# ESP32-P4 register map
Vendor: ESPRESSIF SYSTEMS (SHANGHAI) CO., LTD.; Series: ESP32 P-Series; File version: 3
CPU: RV32IMAFC r0p0, little endian, no MPU, FPU, 0 interrupt priority bits
Address unit: 32 bits
Registers are 32-bit, read-write, reset 0x0 unless marked. A register's access mark holds for its fields unless they carry their own. Offsets are from the block's base; [hi:lo] are bit positions; {n}, {i} and the like mark numbered series.

## LP_WDT — Low-power Watchdog Timer
Base 0x50116000
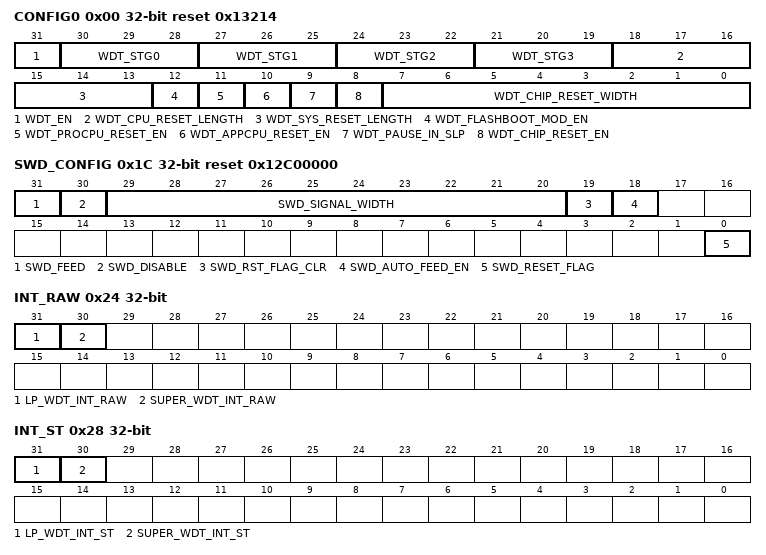
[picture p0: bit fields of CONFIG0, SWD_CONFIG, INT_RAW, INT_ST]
0x00 CONFIG0 reset 0x13214 — need_des
  [31] WDT_EN — need_des
  [30-3n:28-3n] WDT_STG{n} (n=0..3) — need_des
  [18:16] WDT_CPU_RESET_LENGTH — need_des
  [15:13] WDT_SYS_RESET_LENGTH — need_des
  [12] WDT_FLASHBOOT_MOD_EN — need_des
  [11] WDT_PROCPU_RESET_EN — need_des
  [10] WDT_APPCPU_RESET_EN — need_des
  [9] WDT_PAUSE_IN_SLP — need_des
  [8] WDT_CHIP_RESET_EN — need_des
  [7:0] WDT_CHIP_RESET_WIDTH — need_des
0x04 CONFIG1 reset 0x30D40 — need_des
  [31:0] WDT_STG0_HOLD
0x08 CONFIG2 reset 0x13880 — need_des
  [31:0] WDT_STG1_HOLD
0x0C CONFIG3 reset 0xFFF — need_des
  [31:0] WDT_STG2_HOLD
0x10 CONFIG4 reset 0xFFF — need_des
  [31:0] WDT_STG3_HOLD
0x14 FEED wo — need_des
  [31] FEED
0x18 WPROTECT — need_des
  [31:0] WDT_WKEY
0x1C SWD_CONFIG access per field reset 0x12C00000 — need_des
  [31] SWD_FEED wo — need_des
  [30] SWD_DISABLE rw — need_des
  [29:20] SWD_SIGNAL_WIDTH rw — need_des
  [19] SWD_RST_FLAG_CLR wo — need_des
  [18] SWD_AUTO_FEED_EN rw — need_des
  [0] SWD_RESET_FLAG ro — need_des
0x20 SWD_WPROTECT — need_des
  [31:0] SWD_WKEY
0x24 INT_RAW — need_des
  [31] LP_WDT_INT_RAW — need_des
  [30] SUPER_WDT_INT_RAW — need_des
0x28 INT_ST ro — need_des
  [31] LP_WDT_INT_ST — need_des
  [30] SUPER_WDT_INT_ST — need_des
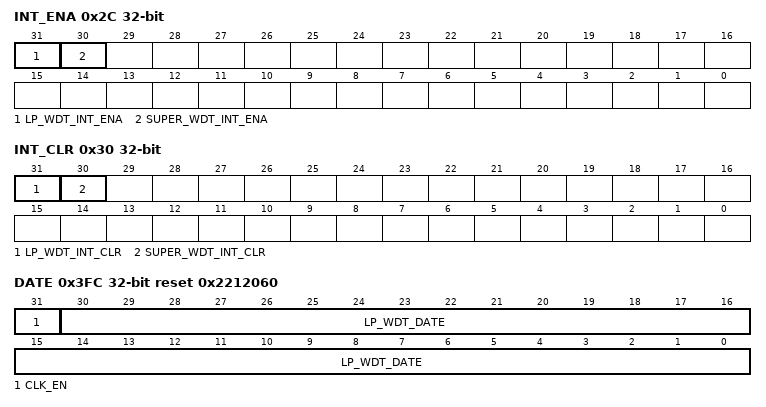
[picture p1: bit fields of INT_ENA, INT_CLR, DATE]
0x2C INT_ENA — need_des
  [31] LP_WDT_INT_ENA — need_des
  [30] SUPER_WDT_INT_ENA — need_des
0x30 INT_CLR wo — need_des
  [31] LP_WDT_INT_CLR — need_des
  [30] SUPER_WDT_INT_CLR — need_des
0x3FC DATE reset 0x2212060 — need_des
  [31] CLK_EN — need_des
  [30:0] LP_WDT_DATE — need_des

## SHA — SHA (Secure Hash Algorithm) Accelerator
Base 0x50091000
0x00 MODE — Configures SHA algorithm
  [2:0] MODE — Configures the SHA algorithm. \\ 0: SHA-1\\ 1: SHA-224\\ 2: SHA-256\\ 3: SHA2-384\\ 4: SHA2-512\\ 5: SHA2-512/224\\ 6: SHA2-512/256\\ 7: SHA2-512/t\\
0x04 T_STRING — SHA 512/t configuration register 0.
  [31:0] T_STRING — Sha t_string (used if and only if mode == SHA_512/t).
0x08 T_LENGTH — SHA 512/t configuration register 1.
  [6:0] T_LENGTH — Sha t_length (used if and only if mode == SHA_512/t).
0x0C DMA_BLOCK_NUM — Block number register (only effective for DMA-SHA)
  [15:0] DMA_BLOCK_NUM — Configures the DMA-SHA block number.
0x10 START wo — Starts the SHA accelerator for Typical SHA operation
  [0] START — Write 1 to start Typical SHA calculation.
0x14 CONTINUE wo — Continues SHA operation (only effective in Typical SHA mode)
  [0] CONTINUE — Write 1 to continue Typical SHA calculation.
0x18 BUSY ro — Represents if SHA Accelerator is busy or not
  [0] STATE — Represents the states of SHA accelerator. \\ 0: idle\\ 1: busy\\
0x1C DMA_START wo — Starts the SHA accelerator for DMA-SHA operation
  [0] DMA_START — Write 1 to start DMA-SHA calculation.
0x20 DMA_CONTINUE wo — Continues SHA operation (only effective in DMA-SHA mode)
  [0] DMA_CONTINUE — Write 1 to continue DMA-SHA calculation.
0x24 CLEAR_IRQ wo — DMA-SHA interrupt clear register
  [0] CLEAR_INTERRUPT — Write 1 to clear DMA-SHA interrupt.
0x28 IRQ_ENA — DMA-SHA interrupt enable register
  [0] INTERRUPT_ENA — Write 1 to enable DMA-SHA interrupt.
0x2C DATE reset 0x20240823 — Version control register
  [29:0] DATE — Version control register.
0x30 DMA_RX_RESET wo — DMA RX FIFO Reset Signal
  [0] DMA_RX_RESET — Write 1 to reset DMA RX FIFO
{0x40+i} H_MEM[{i}] (i=0..63) 8-bit access not given — Sha H memory which contains intermediate hash or finial hash.
{0x80+i} M_MEM[{i}] (i=0..127) 8-bit access not given — Sha M memory which contains message.
